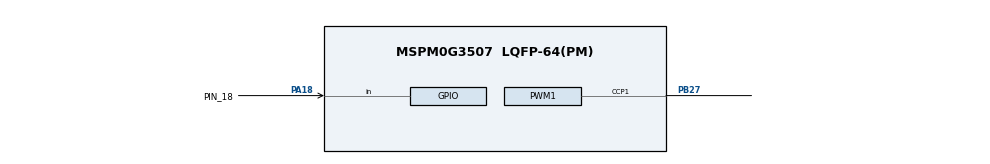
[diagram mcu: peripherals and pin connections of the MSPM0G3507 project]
/**
 * AI AGENTS: Do not edit this file directly. There is no validation or error feedback when
 * editing manually — mistakes will be silent until the file is loaded in SysConfig.
 * Use the SysConfig MCP server instead to make changes with immediate error reporting.
 *
 * These arguments were used when this file was generated. They will be automatically applied on subsequent loads
 * via the GUI or CLI. Run CLI with '--help' for additional information on how to override these arguments.
 * @cliArgs --device "MSPM0G350X" --part "Default" --package "LQFP-64(PM)" --product "mspm0_sdk@2.11.00.07"
 * @v2CliArgs --device "MSPM0G3507" --package "LQFP-64(PM)" --product "mspm0_sdk@2.11.00.07"
 * @versions {"tool":"1.28.1+4785"}
 */

/**
 * Import the modules used in this configuration.
 */
const GPIO    = scripting.addModule("/ti/driverlib/GPIO", {}, false);
const GPIO1   = GPIO.addInstance();
const PWM     = scripting.addModule("/ti/driverlib/PWM", {}, false);
const PWM1    = PWM.addInstance();
const SYSCTL  = scripting.addModule("/ti/driverlib/SYSCTL");
const SYSTICK = scripting.addModule("/ti/driverlib/SYSTICK");
const TIMER   = scripting.addModule("/ti/driverlib/TIMER", {}, false);
const TIMER1  = TIMER.addInstance();

/**
 * Write custom configuration values to the imported modules.
 */
GPIO1.$name                         = "KEY1";
GPIO1.port                          = "PORTA";
GPIO1.associatedPins.create(2);
GPIO1.associatedPins[0].$name       = "PIN_28";
GPIO1.associatedPins[0].direction   = "INPUT";
GPIO1.associatedPins[0].assignedPin = "28";
GPIO1.associatedPins[1].$name       = "PIN_18";
GPIO1.associatedPins[1].direction   = "INPUT";
GPIO1.associatedPins[1].assignedPin = "18";
GPIO1.associatedPins[1].interruptEn = true;
GPIO1.associatedPins[1].polarity    = "RISE";
GPIO1.associatedPins[1].pin.$assign = "PA18";

const Board = scripting.addModule("/ti/driverlib/Board", {}, false);

PWM1.$name                      = "PWM_LED";
PWM1.clockDivider               = 8;
PWM1.clockPrescale              = 100;
PWM1.pwmMode                    = "EDGE_ALIGN_UP";
PWM1.ccIndex                    = [1];
PWM1.timerStartTimer            = true;
PWM1.peripheral.$assign         = "TIMG6";
PWM1.peripheral.ccp1Pin.$assign = "PB27";
PWM1.PWM_CHANNEL_1.$name        = "ti_driverlib_pwm_PWMTimerCC0";
PWM1.ccp1PinConfig.$name        = "ti_driverlib_gpio_GPIOPinGeneric0";

SYSCTL.forceDefaultClkConfig = true;

SYSTICK.periodEnable      = true;
SYSTICK.period            = 32000;
SYSTICK.interruptEnable   = true;
SYSTICK.systickEnable     = true;
SYSTICK.interruptPriority = "0";

TIMER1.$name              = "TIMER_0";
TIMER1.timerClkDiv        = 8;
TIMER1.timerClkPrescale   = 100;
TIMER1.timerMode          = "PERIODIC";
TIMER1.timerPeriod        = "1000 ms";
TIMER1.timerStartTimer    = true;
TIMER1.interrupts         = ["ZERO"];
TIMER1.peripheral.$assign = "TIMG0";

/**
 * Pinmux solution for unlocked pins/peripherals. This ensures that minor changes to the automatic solver in a future
 * version of the tool will not impact the pinmux you originally saw.  These lines can be completely deleted in order to
 * re-solve from scratch.
 */
GPIO1.associatedPins[0].pin.$suggestSolution = "PA28";
Board.peripheral.$suggestSolution            = "DEBUGSS";
Board.peripheral.swclkPin.$suggestSolution   = "PA20";
Board.peripheral.swdioPin.$suggestSolution   = "PA19";
SYSCTL.peripheral.$suggestSolution           = "SYSCTL";
